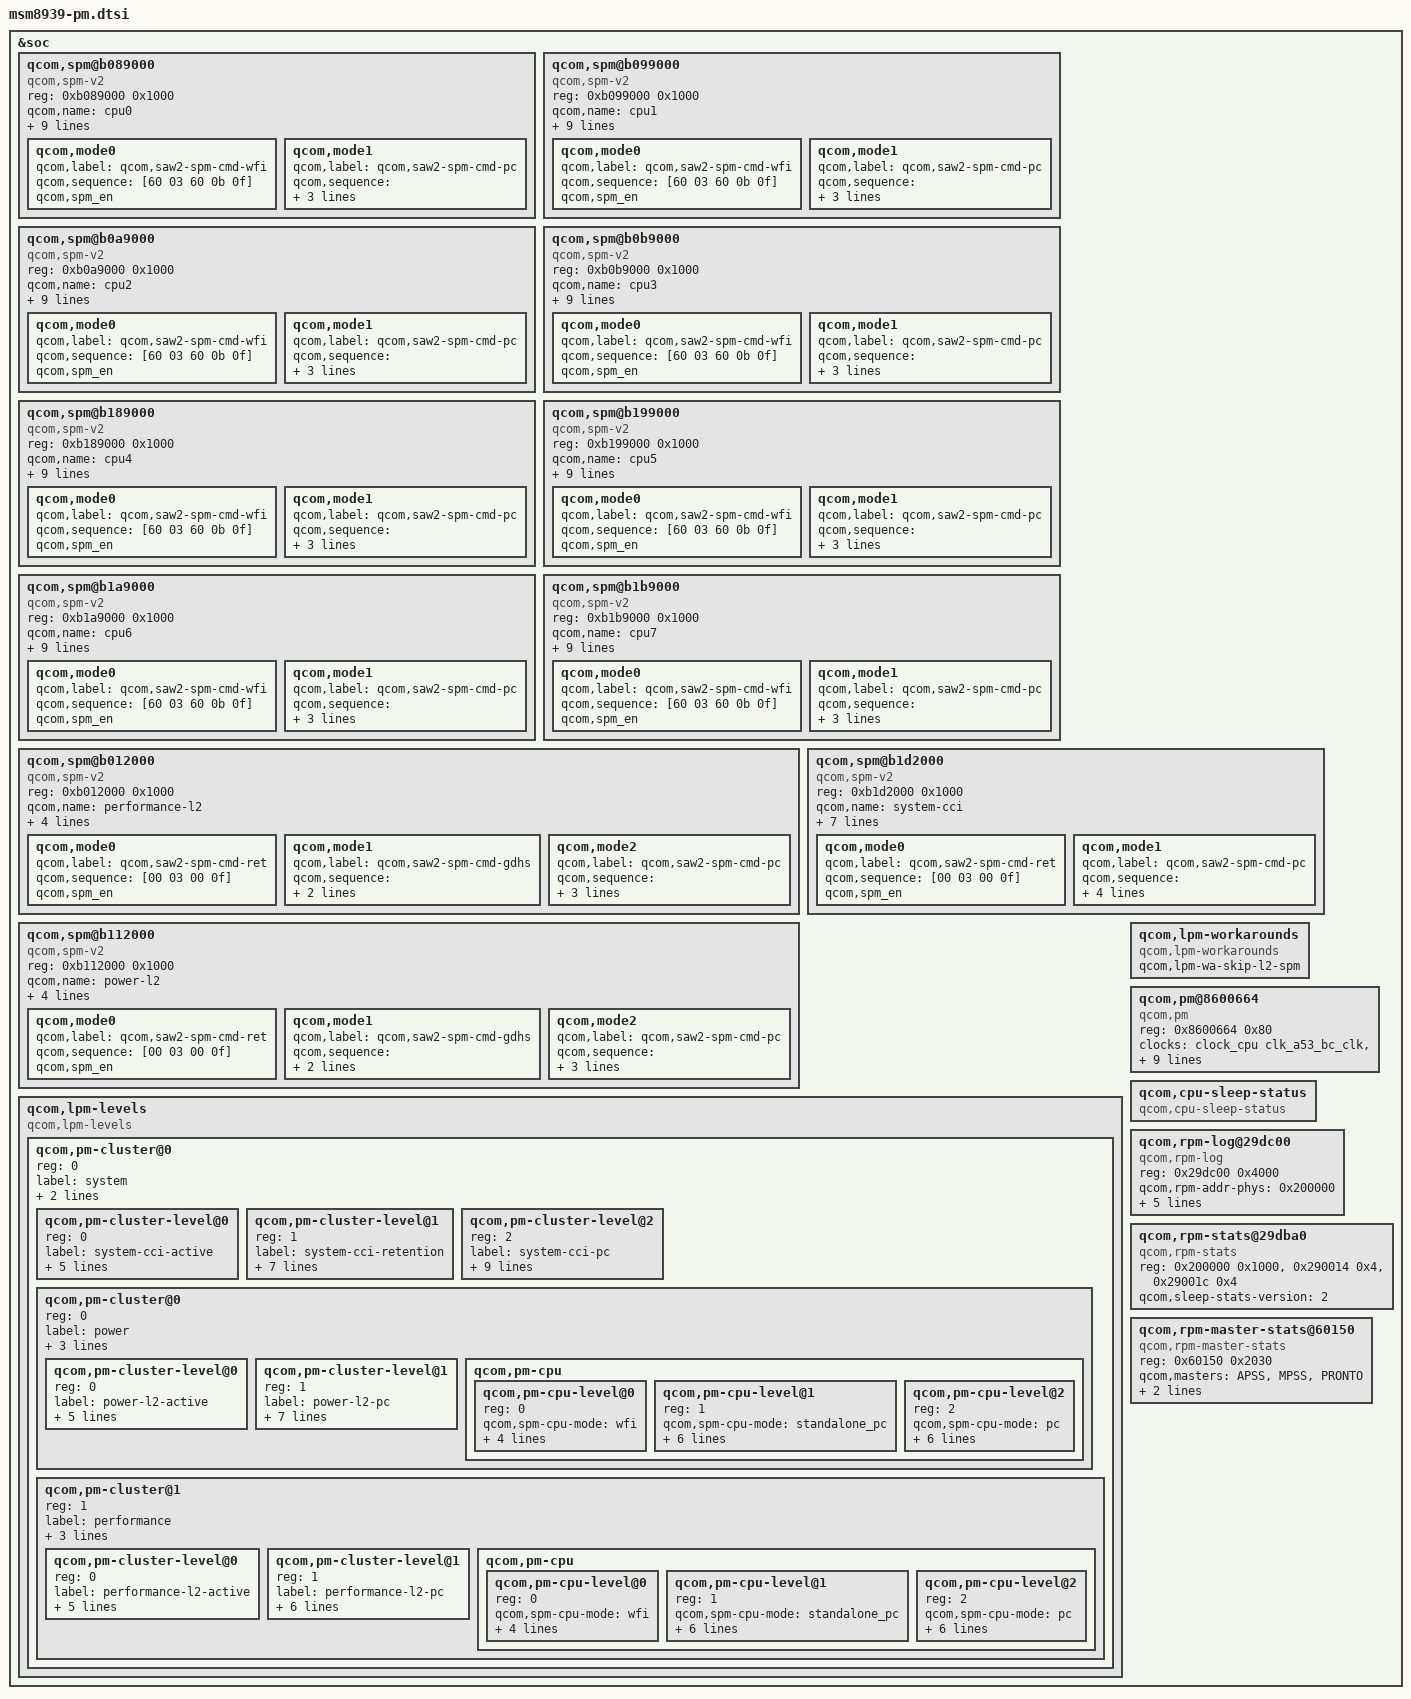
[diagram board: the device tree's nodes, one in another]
/* Copyright (c) 2014-2015, The Linux Foundation. All rights reserved.
 *
 * This program is free software; you can redistribute it and/or modify
 * it under the terms of the GNU General Public License version 2 and
 * only version 2 as published by the Free Software Foundation.
 *
 * This program is distributed in the hope that it will be useful,
 * but WITHOUT ANY WARRANTY; without even the implied warranty of
 * MERCHANTABILITY or FITNESS FOR A PARTICULAR PURPOSE.  See the
 * GNU General Public License for more details.
 */

#include <dt-bindings/msm/pm.h>

&soc {
	qcom,spm@b089000 {
		compatible = "qcom,spm-v2";
		#address-cells = <1>;
		#size-cells = <1>;
		reg = <0xb089000 0x1000>;
		reg-names = "saw-base";
		qcom,name = "cpu0";
		qcom,cpu = <&CPU0>;
		qcom,saw2-ver-reg = <0xfd0>;
		qcom,saw2-cfg = <0x01>;
		qcom,saw2-avs-ctl = <0>;
		qcom,saw2-avs-hysteresis = <0>;
		qcom,saw2-avs-limit = <0>;
		qcom,saw2-avs-dly= <0>;
		qcom,saw2-spm-dly= <0x3c102800>;
		qcom,saw2-spm-ctl = <0xe>;
		qcom,mode0 { 
			qcom,label = "qcom,saw2-spm-cmd-wfi";
			qcom,sequence = [60 03 60 0b 0f];
			qcom,spm_en;
		};
		qcom,mode1 {
			qcom,label = "qcom,saw2-spm-cmd-pc";
			qcom,sequence = [20 50 1b 10 80 30 90 5b 60 50 03 60
				76 76 0b 50 1b 94 5B 80 10 26 30 50 0f];
			qcom,spm_en;
			qcom,pc_mode;
		};
	};

	qcom,spm@b099000 {
		compatible = "qcom,spm-v2";
		#address-cells = <1>;
		#size-cells = <1>;
		reg = <0xb099000 0x1000>;
		reg-names = "saw-base";
		qcom,name = "cpu1";
		qcom,cpu = <&CPU1>;
		qcom,saw2-ver-reg = <0xfd0>;
		qcom,saw2-cfg = <0x01>;
		qcom,saw2-avs-ctl = <0>;
		qcom,saw2-avs-hysteresis = <0>;
		qcom,saw2-avs-limit = <0>;
		qcom,saw2-avs-dly= <0>;
		qcom,saw2-spm-dly= <0x3c102800>;
		qcom,saw2-spm-ctl = <0xe>;
		qcom,mode0 { 
			qcom,label = "qcom,saw2-spm-cmd-wfi";
			qcom,sequence = [60 03 60 0b 0f];
			qcom,spm_en;
		};
		qcom,mode1 {
			qcom,label = "qcom,saw2-spm-cmd-pc";
			qcom,sequence = [20 50 1b 10 80 30 90 5b 60 50 03 60
				76 76 0b 50 1b 94 5B 80 10 26 30 50 0f];
			qcom,spm_en;
			qcom,pc_mode;
		};
	};

	qcom,spm@b0a9000 {
		compatible = "qcom,spm-v2";
		#address-cells = <1>;
		#size-cells = <1>;
		reg = <0xb0a9000 0x1000>;
		reg-names = "saw-base";
		qcom,name = "cpu2";
		qcom,cpu = <&CPU2>;
		qcom,saw2-ver-reg = <0xfd0>;
		qcom,saw2-cfg = <0x01>;
		qcom,saw2-avs-ctl = <0>;
		qcom,saw2-avs-hysteresis = <0>;
		qcom,saw2-avs-limit = <0>;
		qcom,saw2-avs-dly= <0>;
		qcom,saw2-spm-dly= <0x3c102800>;
		qcom,saw2-spm-ctl = <0xe>;
		qcom,mode0 { 
			qcom,label = "qcom,saw2-spm-cmd-wfi";
			qcom,sequence = [60 03 60 0b 0f];
			qcom,spm_en;
		};
		qcom,mode1 {
			qcom,label = "qcom,saw2-spm-cmd-pc";
			qcom,sequence = [20 50 1b 10 80 30 90 5b 60 50 03 60
				76 76 0b 50 1b 94 5B 80 10 26 30 50 0f];
			qcom,spm_en;
			qcom,pc_mode;
		};
	};

	qcom,spm@b0b9000 {
		compatible = "qcom,spm-v2";
		#address-cells = <1>;
		#size-cells = <1>;
		reg = <0xb0b9000 0x1000>;
		reg-names = "saw-base";
		qcom,name = "cpu3";
		qcom,cpu = <&CPU3>;
		qcom,saw2-ver-reg = <0xfd0>;
		qcom,saw2-cfg = <0x01>;
		qcom,saw2-avs-ctl = <0>;
		qcom,saw2-avs-hysteresis = <0>;
		qcom,saw2-avs-limit = <0>;
		qcom,saw2-avs-dly= <0>;
		qcom,saw2-spm-dly= <0x3c102800>;
		qcom,saw2-spm-ctl = <0xe>;
		qcom,mode0 { 
			qcom,label = "qcom,saw2-spm-cmd-wfi";
			qcom,sequence = [60 03 60 0b 0f];
			qcom,spm_en;
		};
		qcom,mode1 {
			qcom,label = "qcom,saw2-spm-cmd-pc";
			qcom,sequence = [20 50 1b 10 80 30 90 5b 60 50 03 60
				76 76 0b 50 1b 94 5B 80 10 26 30 50 0f];
			qcom,spm_en;
			qcom,pc_mode;
		};
	};

	qcom,spm@b189000 {
		compatible = "qcom,spm-v2";
		#address-cells = <1>;
		#size-cells = <1>;
		reg = <0xb189000 0x1000>;
		reg-names = "saw-base";
		qcom,name = "cpu4";
		qcom,cpu = <&CPU4>;
		qcom,saw2-ver-reg = <0xfd0>;
		qcom,saw2-cfg = <0x01>;
		qcom,saw2-avs-ctl = <0>;
		qcom,saw2-avs-hysteresis = <0>;
		qcom,saw2-avs-limit = <0>;
		qcom,saw2-avs-dly= <0>;
		qcom,saw2-spm-dly= <0x3c102800>;
		qcom,saw2-spm-ctl = <0xe>;
		qcom,mode0 { 
			qcom,label = "qcom,saw2-spm-cmd-wfi";
			qcom,sequence = [60 03 60 0b 0f];
			qcom,spm_en;
		};
		qcom,mode1 {
			qcom,label = "qcom,saw2-spm-cmd-pc";
			qcom,sequence = [20 50 1b 10 80 30 90 5b 60 50 03 60
				76 76 0b 50 1b 94 5B 80 10 26 30 50 0f];
			qcom,spm_en;
			qcom,pc_mode;
		};
	};

	qcom,spm@b199000 {
		compatible = "qcom,spm-v2";
		#address-cells = <1>;
		#size-cells = <1>;
		reg = <0xb199000 0x1000>;
		reg-names = "saw-base";
		qcom,name = "cpu5";
		qcom,cpu = <&CPU5>;
		qcom,saw2-ver-reg = <0xfd0>;
		qcom,saw2-cfg = <0x01>;
		qcom,saw2-avs-ctl = <0>;
		qcom,saw2-avs-hysteresis = <0>;
		qcom,saw2-avs-limit = <0>;
		qcom,saw2-avs-dly= <0>;
		qcom,saw2-spm-dly= <0x3c102800>;
		qcom,saw2-spm-ctl = <0xe>;
		qcom,mode0 { 
			qcom,label = "qcom,saw2-spm-cmd-wfi";
			qcom,sequence = [60 03 60 0b 0f];
			qcom,spm_en;
		};
		qcom,mode1 {
			qcom,label = "qcom,saw2-spm-cmd-pc";
			qcom,sequence = [20 50 1b 10 80 30 90 5b 60 50 03 60
				76 76 0b 50 1b 94 5B 80 10 26 30 50 0f];
			qcom,spm_en;
			qcom,pc_mode;
		};
	};

	qcom,spm@b1a9000 {
		compatible = "qcom,spm-v2";
		#address-cells = <1>;
		#size-cells = <1>;
		reg = <0xb1a9000 0x1000>;
		reg-names = "saw-base";
		qcom,name = "cpu6";
		qcom,cpu = <&CPU6>;
		qcom,saw2-ver-reg = <0xfd0>;
		qcom,saw2-cfg = <0x01>;
		qcom,saw2-avs-ctl = <0>;
		qcom,saw2-avs-hysteresis = <0>;
		qcom,saw2-avs-limit = <0>;
		qcom,saw2-avs-dly= <0>;
		qcom,saw2-spm-dly= <0x3c102800>;
		qcom,saw2-spm-ctl = <0xe>;
		qcom,mode0 { 
			qcom,label = "qcom,saw2-spm-cmd-wfi";
			qcom,sequence = [60 03 60 0b 0f];
			qcom,spm_en;
		};
		qcom,mode1 {
			qcom,label = "qcom,saw2-spm-cmd-pc";
			qcom,sequence = [20 50 1b 10 80 30 90 5b 60 50 03 60
				76 76 0b 50 1b 94 5B 80 10 26 30 50 0f];
			qcom,spm_en;
			qcom,pc_mode;
		};
	};

	qcom,spm@b1b9000 {
		compatible = "qcom,spm-v2";
		#address-cells = <1>;
		#size-cells = <1>;
		reg = <0xb1b9000 0x1000>;
		reg-names = "saw-base";
		qcom,name = "cpu7";
		qcom,cpu = <&CPU7>;
		qcom,saw2-ver-reg = <0xfd0>;
		qcom,saw2-cfg = <0x01>;
		qcom,saw2-avs-ctl = <0>;
		qcom,saw2-avs-hysteresis = <0>;
		qcom,saw2-avs-limit = <0>;
		qcom,saw2-avs-dly= <0>;
		qcom,saw2-spm-dly= <0x3c102800>;
		qcom,saw2-spm-ctl = <0xe>;
		qcom,mode0 { 
			qcom,label = "qcom,saw2-spm-cmd-wfi";
			qcom,sequence = [60 03 60 0b 0f];
			qcom,spm_en;
		};
		qcom,mode1 {
			qcom,label = "qcom,saw2-spm-cmd-pc";
			qcom,sequence = [20 50 1b 10 80 30 90 5b 60 50 03 60
				76 76 0b 50 1b 94 5B 80 10 26 30 50 0f];
			qcom,spm_en;
			qcom,pc_mode;
		};
	};

	qcom,spm@b012000 {
		compatible = "qcom,spm-v2";
		#address-cells = <1>;
		#size-cells = <1>;
		reg = <0xb012000 0x1000>;
		reg-names = "saw-base";
		qcom,name = "performance-l2";
		qcom,saw2-ver-reg = <0xfd0>;
		qcom,saw2-cfg = <0x1>;
		qcom,saw2-spm-dly= <0x3C11840A>;
		qcom,saw2-spm-ctl = <0xe>;
		qcom,mode0 {
			qcom,label = "qcom,saw2-spm-cmd-ret";
			qcom,sequence = [00 03 00 0f];
			qcom,spm_en;
		};
		qcom,mode1 { 
			qcom,label = "qcom,saw2-spm-cmd-gdhs";
			qcom,sequence = [00 b0 7b 20 32 6b c0 e0 d0 50 42 f0 b0
				03 1f 1b b0 7b 4e 02 02 d0 e0 c0 22 6b 02 32 52
				f0 b0 0f];
			qcom,spm_en;
		};
		qcom,mode2 {
			qcom,label = "qcom,saw2-spm-cmd-pc";
			qcom,sequence = [00 b0 7b 32 10 e0 d0 6b c0 50 42 b0 03
				1f 1b b0 7b 4e 02 02 c0 d0 12 e0 6b 02 32 50 b0 0f];
			qcom,spm_en;
			qcom,pc_mode;
		};
	};

	qcom,spm@b112000 {
		compatible = "qcom,spm-v2";
		#address-cells = <1>;
		#size-cells = <1>;
		reg = <0xb112000 0x1000>;
		reg-names = "saw-base";
		qcom,name = "power-l2";
		qcom,saw2-ver-reg = <0xfd0>;
		qcom,saw2-cfg = <0x1>;
		qcom,saw2-spm-dly= <0x3C11840A>;
		qcom,saw2-spm-ctl = <0xe>;
		qcom,mode0 {
			qcom,label = "qcom,saw2-spm-cmd-ret";
			qcom,sequence = [00 03 00 0f];
			qcom,spm_en;
		};
		qcom,mode1 { 
			qcom,label = "qcom,saw2-spm-cmd-gdhs";
			qcom,sequence = [00 b0 7b 20 32 6b c0 e0 d0 50 42 f0 b0
				03 1f 1b b0 7b 4e 02 02 d0 e0 c0 22 6b 02 32 52
				f0 b0 0f];
			qcom,spm_en;
		};
		qcom,mode2 {
			qcom,label = "qcom,saw2-spm-cmd-pc";
			qcom,sequence = [00 b0 7b 32 10 e0 d0 6b c0 50 42 b0 03
				1f 1b b0 7b 4e 02 02 c0 d0 12 e0 6b 02 32 50 b0 0f];
			qcom,spm_en;
			qcom,pc_mode;
		};
	};

	qcom,spm@b1d2000 {
		compatible = "qcom,spm-v2";
		#address-cells = <1>;
		#size-cells = <1>;
		reg = <0xb1d2000 0x1000>;
		reg-names = "saw-base";
		qcom,name = "system-cci";
		qcom,supports-rpm-hs;
		qcom,saw2-ver-reg = <0xfd0>;
		qcom,saw2-cfg = <0x14>;
		qcom,saw2-spm-dly= <0x3C102800>;
		qcom,saw2-spm-ctl = <0xe>;
		qcom,saw2-pmic-data0 = <0x07030011>;
		qcom,saw2-pmic-data1 = <0x00030010>;
                qcom,mode0 {
			qcom,label = "qcom,saw2-spm-cmd-ret";
			qcom,sequence = [00 03 00 0f];
			qcom,spm_en;
		};
                qcom,mode1 { 
			qcom,label = "qcom,saw2-spm-cmd-pc";
			qcom,sequence = [00 60 50 11 03 70 7B 01 50
                                02 62 72 0f];
			qcom,pc_mode;
			qcom,slp_cmd_mode;
			qcom,spm_en;
		};
	};

	qcom,lpm-levels {
		compatible = "qcom,lpm-levels";
		#address-cells = <1>;
		#size-cells = <0>;

		qcom,pm-cluster@0 {
			reg = <0>;
			#address-cells = <1>;
			#size-cells = <0>;
			label = "system";
			qcom,spm-device-names = "cci";
			qcom,default-level=<0>;

			qcom,pm-cluster-level@0{
				reg = <0>;
				label = "system-cci-active";
				qcom,spm-cci-mode = "active";
				qcom,latency-us = <530>;
				qcom,ss-power = <510>;
				qcom,energy-overhead = <670000>;
				qcom,time-overhead = <1000>;
			};

			qcom,pm-cluster-level@1{
				reg = <1>;
				label = "system-cci-retention";
				qcom,spm-cci-mode = "retention";
				qcom,latency-us = <560>;
				qcom,ss-power = <486>;
				qcom,energy-overhead = <770000>;
				qcom,time-overhead = <1100>;
				qcom,min-child-idx = <1>;
				qcom,reset-level = <LPM_RESET_LVL_RET>;
			};

			qcom,pm-cluster-level@2{
				reg = <2>;
				label = "system-cci-pc";
				qcom,spm-cci-mode = "pc";
				qcom,latency-us = <11500>;
				qcom,ss-power = <464>;
				qcom,energy-overhead = <1525000>;
				qcom,time-overhead = <2500>;
				qcom,min-child-idx = <1>;
				qcom,notify-rpm;
				qcom,disable-dynamic-int-routing;
				qcom,reset-level = <LPM_RESET_LVL_PC>;
			};

			qcom,pm-cluster@0{
				reg = <0>;
				#address-cells = <1>;
				#size-cells = <0>;
				label = "power";
				qcom,spm-device-names = "l2";
				qcom,default-level=<0>;
				qcom,cpu = <&CPU4 &CPU5 &CPU6 &CPU7>;

				qcom,pm-cluster-level@0{
					reg = <0>;
					label = "power-l2-active";
					qcom,spm-l2-mode = "active";
					qcom,latency-us = <26>;
					qcom,ss-power = <530>;
					qcom,energy-overhead = <400000>;
					qcom,time-overhead = <520>;
				};

				qcom,pm-cluster-level@1{
					reg = <1>;
					label = "power-l2-pc";
					qcom,spm-l2-mode = "pc";
					qcom,latency-us = <530>;
					qcom,ss-power = <510>;
					qcom,energy-overhead = <670000>;
					qcom,time-overhead = <1000>;
					qcom,min-child-idx = <2>;
					qcom,reset-level = <LPM_RESET_LVL_PC>;
				};

				qcom,pm-cpu {
					#address-cells = <1>;
					#size-cells = <0>;

					qcom,pm-cpu-level@0 {
						reg = <0>;
						qcom,spm-cpu-mode = "wfi";
						qcom,latency-us = <1>;
						qcom,ss-power = <600>;
						qcom,energy-overhead = <80000>;
						qcom,time-overhead = <60>;
					};

					qcom,pm-cpu-level@1 {
						reg = <1>;
						qcom,spm-cpu-mode = "standalone_pc";
						qcom,latency-us = <190>;
						qcom,ss-power = <550>;
						qcom,energy-overhead = <315000>;
						qcom,time-overhead = <400>;
						qcom,use-broadcast-timer;
						qcom,reset-level =
							<LPM_RESET_LVL_PC>;
					};

					qcom,pm-cpu-level@2 {
						reg = <2>;
						qcom,spm-cpu-mode = "pc";
						qcom,latency-us = <260>;
						qcom,ss-power = <530>;
						qcom,energy-overhead = <400000>;
						qcom,time-overhead = <520>;
						qcom,use-broadcast-timer;
						qcom,reset-level =
							<LPM_RESET_LVL_PC>;
					};
				};
			};

			qcom,pm-cluster@1{
				reg = <1>;
				#address-cells = <1>;
				#size-cells = <0>;
				label = "performance";
				qcom,spm-device-names = "l2";
				qcom,default-level=<0>;
				qcom,cpu = <&CPU0 &CPU1 &CPU2 &CPU3>;

				qcom,pm-cluster-level@0{
					reg = <0>;
					label = "performance-l2-active";
					qcom,spm-l2-mode = "active";
					qcom,latency-us = <260>;
					qcom,ss-power = <610>;
					qcom,energy-overhead = <410000>;
					qcom,time-overhead = <470>;
				};

				qcom,pm-cluster-level@1{
					reg = <1>;
					label = "performance-l2-pc";
					qcom,spm-l2-mode = "pc";
					qcom,latency-us = <450>;
					qcom,ss-power = <502>;
					qcom,energy-overhead = <750000>;
					qcom,time-overhead = <920>;
					qcom,min-child-idx = <2>;
				};

				qcom,pm-cpu {
					#address-cells = <1>;
					#size-cells = <0>;

					qcom,pm-cpu-level@0 {
						reg = <0>;
						qcom,spm-cpu-mode = "wfi";
						qcom,latency-us = <1>;
						qcom,ss-power = <670>;
						qcom,energy-overhead = <80000>;
						qcom,time-overhead = <20>;
					};

					qcom,pm-cpu-level@1 {
						reg = <1>;
						qcom,spm-cpu-mode = "standalone_pc";
						qcom,latency-us = <170>;
						qcom,ss-power = <642>;
						qcom,energy-overhead = <294000>;
						qcom,time-overhead = <330>;
						qcom,use-broadcast-timer;
						qcom,reset-level =
							<LPM_RESET_LVL_PC>;
					};

					qcom,pm-cpu-level@2 {
						reg = <2>;
						qcom,spm-cpu-mode = "pc";
						qcom,latency-us = <260>;
						qcom,ss-power = <610>;
						qcom,energy-overhead = <410000>;
						qcom,time-overhead = <470>;
						qcom,use-broadcast-timer;
						qcom,reset-level =
							<LPM_RESET_LVL_PC>;
					};
				};
			};
		};
	};

	qcom,lpm-workarounds {
		compatible = "qcom,lpm-workarounds";
		qcom,lpm-wa-skip-l2-spm;
	};

	qcom,pm@8600664 {
		compatible = "qcom,pm";
		#address-cells = <1>;
		#size-cells = <1>;
		ranges;
		reg = <0x8600664 0x80>;
		clock-names =
			"cpu0_clk", "cpu1_clk", "cpu2_clk",
			"cpu3_clk", "cpu4_clk", "cpu5_clk",
			"cpu6_clk", "cpu7_clk", "l2_clk";
		clocks = <&clock_cpu clk_a53_bc_clk>,
			 <&clock_cpu clk_a53_bc_clk>,
			 <&clock_cpu clk_a53_bc_clk>,
			 <&clock_cpu clk_a53_bc_clk>,
			 <&clock_cpu clk_a53_lc_clk>,
			 <&clock_cpu clk_a53_lc_clk>,
			 <&clock_cpu clk_a53_lc_clk>,
			 <&clock_cpu clk_a53_lc_clk>,
			 <&clock_cpu clk_cci_clk>;

		qcom,tz-flushes-cache;
	};

	qcom,cpu-sleep-status{
		compatible = "qcom,cpu-sleep-status";
	};

	qcom,rpm-log@29dc00 {
		compatible = "qcom,rpm-log";
		reg = <0x29dc00 0x4000>;
		qcom,rpm-addr-phys = <0x200000>;
		qcom,offset-version = <4>;
		qcom,offset-page-buffer-addr = <36>;
		qcom,offset-log-len = <40>;
		qcom,offset-log-len-mask = <44>;
		qcom,offset-page-indices = <56>;
	};

	qcom,rpm-stats@29dba0 {
		compatible = "qcom,rpm-stats";
		reg = <0x200000 0x1000>,
		      <0x290014 0x4>,
		      <0x29001c 0x4>;
		reg-names = "phys_addr_base", "offset_addr", "heap_phys_addrbase";
		qcom,sleep-stats-version = <2>;
	};

	qcom,rpm-master-stats@60150 {
		compatible = "qcom,rpm-master-stats";
		reg = <0x60150 0x2030>;
		qcom,masters = "APSS", "MPSS", "PRONTO";
		qcom,master-stats-version = <2>;
		qcom,master-offset = <4096>;
	};

/*
	qcom,rpm-rbcpr-stats@0x29daa0  {
		compatible = "qcom,rpmrbcpr-stats";
		reg = <0x29daa0 0x1a0000>;
		qcom,start-offset = <0x190010>;
	};
*/
};
